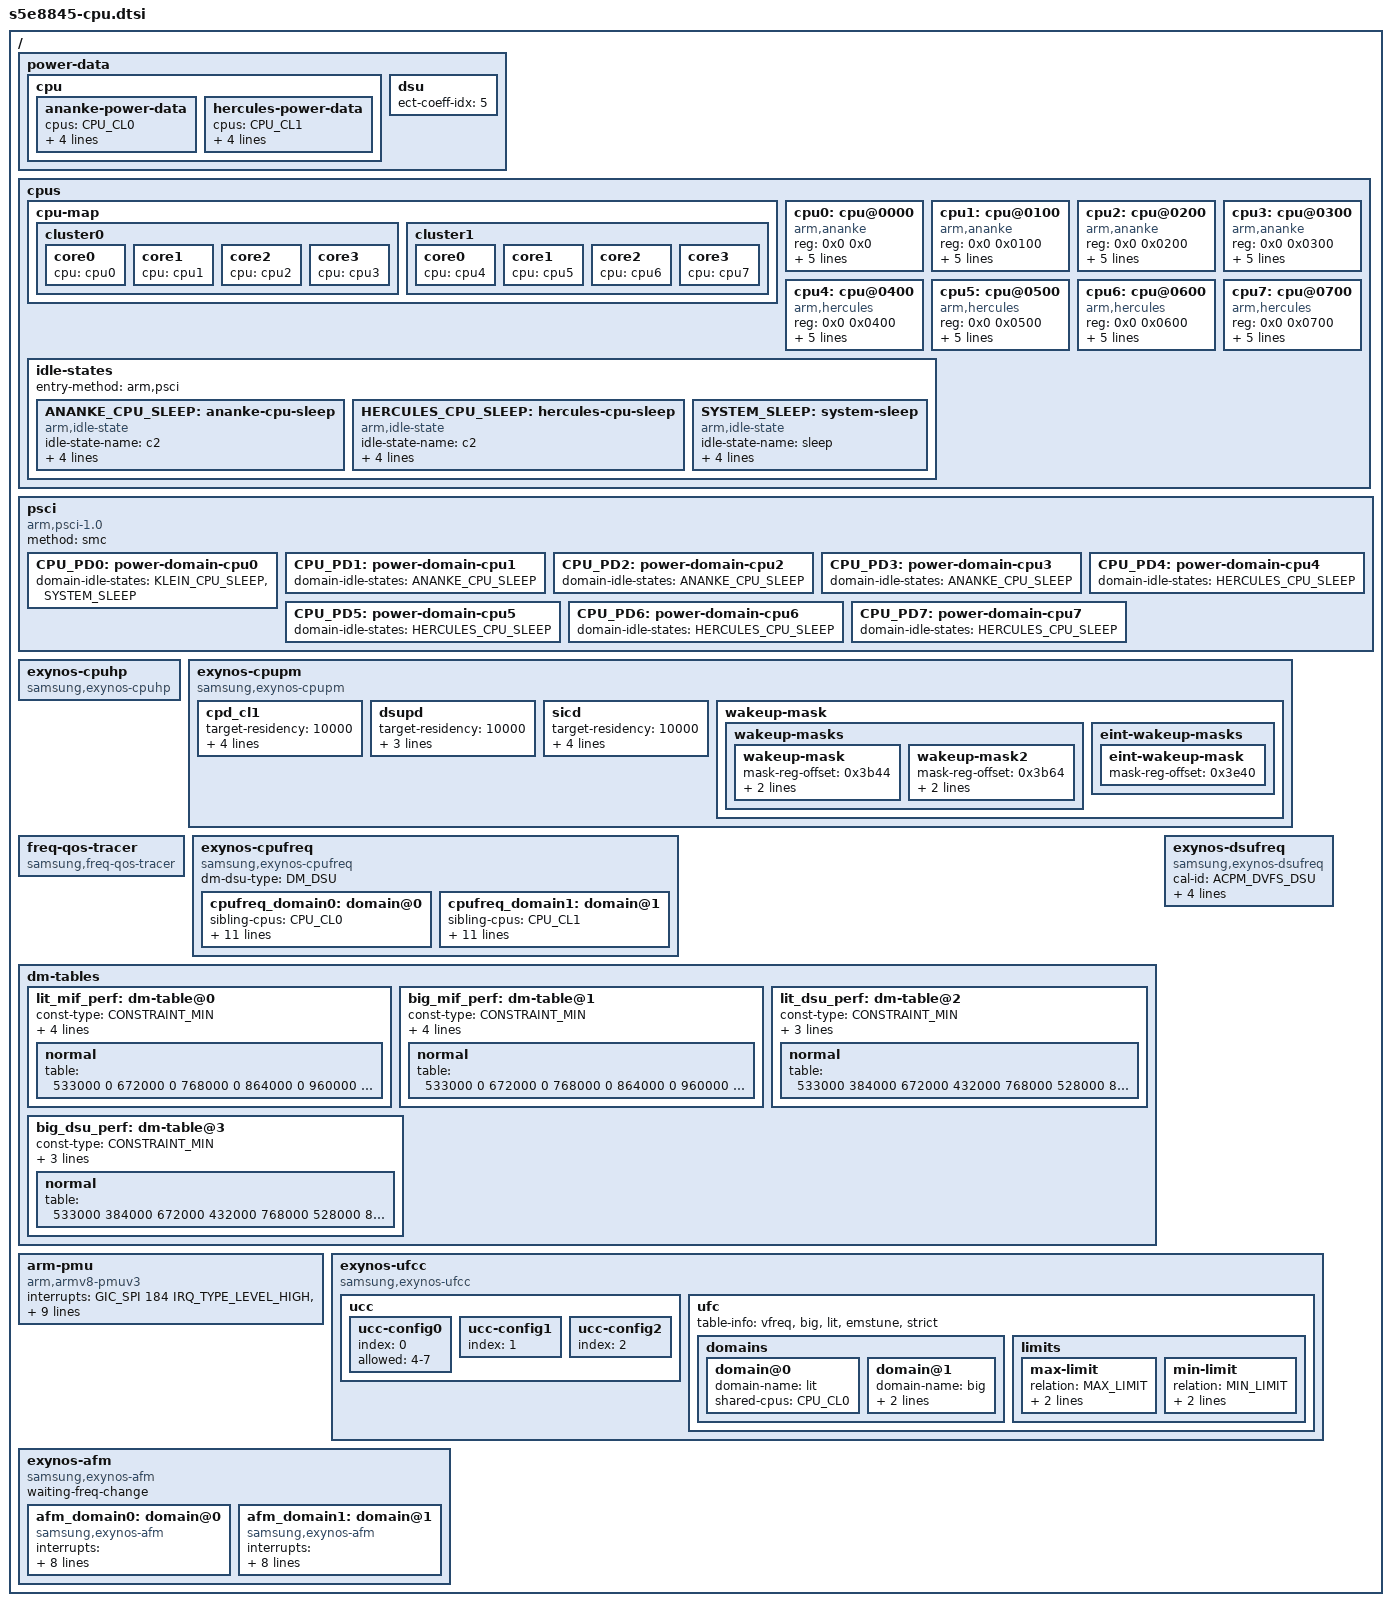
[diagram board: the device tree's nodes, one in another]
/*
 * SAMSUNG S5E8845 SoC CPU device tree source
 *
 * Copyright (c) 2023 Samsung Electronics Co., Ltd.
 *             http://www.samsung.com
 *
 * SAMSUNG EXYNOS8845 SoC device nodes are listed in this file.
 * EXYNOS based board files can include this file and provide
 * values for board specfic bindings.
 *
 * This program is free software; you can redistribute it and/or modify
 * it under the terms of the GNU General Public License version 2 as
 * published by the Free Software Foundation.
 */

#include <dt-bindings/soc/samsung/cpupm.h>

/ {

	power-data {

		#define CPU_CL0 "0-3"
		#define CPU_CL1 "4-7"
		#define CPU_ALL "0-7"

		#define CPUCL0_DMIPS_PER_MHZ 380
		#define CPUCL1_DMIPS_PER_MHZ 900

		#define CPUCL0_DP_COEFF 80
		#define CPUCL1_DP_COEFF 517

		cpu {
			ananke-power-data {
				/* default power data */
				cpus = CPU_CL0;
				capacity-dmips-mhz = <CPUCL0_DMIPS_PER_MHZ>;
				dynamic-power-coefficient = <CPUCL0_DP_COEFF>;
				tz-name = "LITTLE";

				/* dynamic power w/ ECT */
				ect-coeff-idx = <1>;
			};
			hercules-power-data {
				/* default power data */
				cpus = CPU_CL1;
				capacity-dmips-mhz = <CPUCL1_DMIPS_PER_MHZ>;
				dynamic-power-coefficient = <CPUCL1_DP_COEFF>;
				tz-name = "BIG";

				/* dynamic power w/ ECT */
				ect-coeff-idx = <0>;
			};
		};
		dsu {
			/* dynamic power w/ ECT */
			ect-coeff-idx = <5>;
		};
	};

	cpus {
		#address-cells = <2>;
		#size-cells = <0>;

		cpu-map {
			cluster0 {
				core0 {
					cpu = <&cpu0>;
				};
				core1 {
					cpu = <&cpu1>;
				};
				core2 {
					cpu = <&cpu2>;
				};
				core3 {
					cpu = <&cpu3>;
				};
			};
			cluster1 {
				core0 {
					cpu = <&cpu4>;
				};
				core1 {
					cpu = <&cpu5>;
				};
				core2 {
					cpu = <&cpu6>;
				};
				core3 {
					cpu = <&cpu7>;
				};
			};
		};

		cpu0: cpu@0000 {
			device_type = "cpu";
			compatible = "arm,ananke", "arm,armv8";
			reg = <0x0 0x0>;
			capacity-dmips-mhz = <CPUCL0_DMIPS_PER_MHZ>;
			dynamic-power-coefficient = <CPUCL0_DP_COEFF>;
			enable-method = "psci";
			cpu-idle-states = <&ANANKE_CPU_SLEEP>;
			power-domains = <&CPU_PD0>;
			power-domain-names = "psci";
		};
		cpu1: cpu@0100 {
			device_type = "cpu";
			compatible = "arm,ananke", "arm,armv8";
			reg = <0x0 0x0100>;
			capacity-dmips-mhz = <CPUCL0_DMIPS_PER_MHZ>;
			dynamic-power-coefficient = <CPUCL0_DP_COEFF>;
			enable-method = "psci";
			cpu-idle-states = <&ANANKE_CPU_SLEEP>;
			power-domains = <&CPU_PD1>;
			power-domain-names = "psci";
		};
		cpu2: cpu@0200 {
			device_type = "cpu";
			compatible = "arm,ananke", "arm,armv8";
			reg = <0x0 0x0200>;
			capacity-dmips-mhz = <CPUCL0_DMIPS_PER_MHZ>;
			dynamic-power-coefficient = <CPUCL0_DP_COEFF>;
			enable-method = "psci";
			cpu-idle-states = <&ANANKE_CPU_SLEEP>;
			power-domains = <&CPU_PD2>;
			power-domain-names = "psci";
		};
		cpu3: cpu@0300 {
			device_type = "cpu";
			compatible = "arm,ananke", "arm,armv8";
			reg = <0x0 0x0300>;
			capacity-dmips-mhz = <CPUCL0_DMIPS_PER_MHZ>;
			dynamic-power-coefficient = <CPUCL0_DP_COEFF>;
			enable-method = "psci";
			cpu-idle-states = <&ANANKE_CPU_SLEEP>;
			power-domains = <&CPU_PD3>;
			power-domain-names = "psci";
		};
		cpu4: cpu@0400 {
			device_type = "cpu";
			compatible = "arm,hercules", "arm,armv8";
			reg = <0x0 0x0400>;
			capacity-dmips-mhz = <CPUCL1_DMIPS_PER_MHZ>;
			dynamic-power-coefficient = <CPUCL1_DP_COEFF>;
			enable-method = "psci";
			cpu-idle-states = <&HERCULES_CPU_SLEEP>;
			power-domains = <&CPU_PD4>;
			power-domain-names = "psci";
		};
		cpu5: cpu@0500 {
			device_type = "cpu";
			compatible = "arm,hercules", "arm,armv8";
			reg = <0x0 0x0500>;
			capacity-dmips-mhz = <CPUCL1_DMIPS_PER_MHZ>;
			dynamic-power-coefficient = <CPUCL1_DP_COEFF>;
			enable-method = "psci";
			cpu-idle-states = <&HERCULES_CPU_SLEEP>;
			power-domains = <&CPU_PD5>;
			power-domain-names = "psci";
		};
		cpu6: cpu@0600 {
			device_type = "cpu";
			compatible = "arm,hercules", "arm,armv8";
			reg = <0x0 0x0600>;
			capacity-dmips-mhz = <CPUCL1_DMIPS_PER_MHZ>;
			dynamic-power-coefficient = <CPUCL1_DP_COEFF>;
			enable-method = "psci";
			cpu-idle-states = <&HERCULES_CPU_SLEEP>;
			power-domains = <&CPU_PD6>;
			power-domain-names = "psci";
		};
		cpu7: cpu@0700 {
			device_type = "cpu";
			compatible = "arm,hercules", "arm,armv8";
			reg = <0x0 0x0700>;
			capacity-dmips-mhz = <CPUCL1_DMIPS_PER_MHZ>;
			dynamic-power-coefficient = <CPUCL1_DP_COEFF>;
			enable-method = "psci";
			cpu-idle-states = <&HERCULES_CPU_SLEEP>;
			power-domains = <&CPU_PD7>;
			power-domain-names = "psci";
		};

		idle-states {
			entry-method = "arm,psci";

			ANANKE_CPU_SLEEP: ananke-cpu-sleep {
				idle-state-name = "c2";
				compatible = "arm,idle-state";
				arm,psci-suspend-param = <0x0010000>;
				entry-latency-us = <70>;
				exit-latency-us = <160>;
				min-residency-us = <2000>;
				status = "okay";
			};

			HERCULES_CPU_SLEEP: hercules-cpu-sleep {
				idle-state-name = "c2";
				compatible = "arm,idle-state";
				arm,psci-suspend-param = <0x0010000>;
				entry-latency-us = <150>;
				exit-latency-us = <190>;
				min-residency-us = <2500>;
				status = "okay";
			};

			SYSTEM_SLEEP: system-sleep {
				idle-state-name = "sleep";
				compatible = "arm,idle-state";
				arm,psci-suspend-param = <0x3010000>;
				entry-latency-us = <2147483647>;
				exit-latency-us = <2147483647>;
				min-residency-us = <4294967295>;
				status = "okay";
			};
		};
	};

	psci {
		compatible = "arm,psci-1.0";
		method = "smc";

		CPU_PD0: power-domain-cpu0 {
		#power-domain-cells = <0>;
		domain-idle-states = <&KLEIN_CPU_SLEEP>, <&SYSTEM_SLEEP>;
		};
		CPU_PD1: power-domain-cpu1 {
		#power-domain-cells = <0>;
		domain-idle-states = <&ANANKE_CPU_SLEEP>;
		};
		CPU_PD2: power-domain-cpu2 {
		#power-domain-cells = <0>;
		domain-idle-states = <&ANANKE_CPU_SLEEP>;
		};
		CPU_PD3: power-domain-cpu3 {
		#power-domain-cells = <0>;
		domain-idle-states = <&ANANKE_CPU_SLEEP>;
		};
		CPU_PD4: power-domain-cpu4 {
		#power-domain-cells = <0>;
		domain-idle-states = <&HERCULES_CPU_SLEEP>;
		};
		CPU_PD5: power-domain-cpu5 {
		#power-domain-cells = <0>;
		domain-idle-states = <&HERCULES_CPU_SLEEP>;
		};
		CPU_PD6: power-domain-cpu6 {
		#power-domain-cells = <0>;
		domain-idle-states = <&HERCULES_CPU_SLEEP>;
		};
		CPU_PD7: power-domain-cpu7 {
		#power-domain-cells = <0>;
		domain-idle-states = <&HERCULES_CPU_SLEEP>;
		};
	};

	exynos-cpuhp {
		compatible = "samsung,exynos-cpuhp";
		status = "okay";
	};

	exynos-cpupm {
		compatible = "samsung,exynos-cpupm";
		status = "okay";

		cpd_cl1 {
			device_type = "cpupm";
			target-residency = <10000>;
			type = <POWERMODE_TYPE_CLUSTER>;
			cal-id = <1>;
			siblings = CPU_CL1;
			entry-allowed = CPU_CL1;
		};

		dsupd {
			device_type = "cpupm";
			target-residency = <10000>;
			type = <POWERMODE_TYPE_DSU>;
			siblings = CPU_ALL;
			entry-allowed = CPU_ALL;
		};

		sicd {
			device_type = "cpupm";
			target-residency = <10000>;
			type = <POWERMODE_TYPE_SYSTEM>;
			siblings = CPU_ALL;
			entry-allowed = CPU_ALL;
			deferred-enabled;
		};

		wakeup-mask {
			wakeup-masks {
				wakeup-mask {
					mask-reg-offset = <0x3b44>;
					stat-reg-offset = <0x3b50>;
					mask = <0xff000000>;
				};
				wakeup-mask2 {
					mask-reg-offset = <0x3b64>;
					stat-reg-offset = <0x3b54>;
					mask = <0x00>;
				};
			};

			eint-wakeup-masks {
				eint-wakeup-mask {
					mask-reg-offset = <0x3e40>;
				};
			};
		};

	};

	freq-qos-tracer {
		compatible = "samsung,freq-qos-tracer";
		status = "okay";
	};

	exynos-cpufreq {
		compatible = "samsung,exynos-cpufreq";
		status = "okay";
		dm-dsu-type = <DM_DSU>;

		cpufreq_domain0: domain@0 {
			sibling-cpus = CPU_CL0;
			cal-id = <ACPM_DVFS_CPUCL0>;
			dm-type = <DM_CPUCL0>;
			dss-type = <ESS_FLAG_CPU_CL0>;

			max-freq = <2050000>;
			min-freq = <533000>;

			fast-switch;
			thread-run-on = "0-3";

			#cooling-cells = <2>; /* min followed by max */
			ect-coeff-index = <1>;
			tz-cooling-name = "LITTLE";

			freq-table = <   533000
					 672000
					 768000
					 864000
					 960000
					1056000
					1152000
					1248000
					1344000
					1440000
					1536000
					1632000
					1728000
					1824000
					1920000
					2050000 >;
		};

		cpufreq_domain1: domain@1 {
			sibling-cpus = CPU_CL1;
			cal-id = <ACPM_DVFS_CPUCL1>;
			dm-type = <DM_CPUCL1>;
			dss-type = <ESS_FLAG_CPU_CL1>;

			max-freq = <2750000>;
			min-freq = <533000>;

			fast-switch;
			thread-run-on = "0-3";

			#cooling-cells = <2>; /* min followed by max */
			ect-coeff-index = <0>;
			tz-cooling-name = "BIG";

			freq-table = <   533000
					 672000
					 768000
					 864000
					 960000
					1056000
					1152000
					1248000
					1344000
					1440000
					1536000
					1632000
					1728000
					1824000
					1920000
					2016000
					2112000
					2208000
					2304000
					2400000
					2496000
					2592000
					2688000
					2750000 >;
		};
	};

	dm-tables {
		lit_mif_perf: dm-table@0 {
			const-type = <CONSTRAINT_MIN>;
			dm-slave = <DM_MIF>;
			master-cal-id = <ACPM_DVFS_CPUCL0>;
			slave-cal-id = <ACPM_DVFS_MIF>;
			dynamic-disable;

			normal {        /* CPU    MIF */
				table = <  533000        0
					   672000        0
					   768000        0
					   864000        0
					   960000        0
					  1056000        0
					  1152000        0
					  1248000        0
					  1344000        0
					  1440000        0
					  1536000        0
					  1632000        0
					  1728000        0
					  1824000        0
					  1920000        0
					  2050000        0 >;
			};
		};
		big_mif_perf: dm-table@1 {
			const-type = <CONSTRAINT_MIN>;
			dm-slave = <DM_MIF>;
			master-cal-id = <ACPM_DVFS_CPUCL1>;
			slave-cal-id = <ACPM_DVFS_MIF>;
			dynamic-disable;

			normal {        /* CPU    MIF */
				table = <  533000        0
					   672000        0
					   768000        0
					   864000        0
					   960000        0
					  1056000        0
					  1152000        0
					  1248000        0
					  1344000        0
					  1440000        0
					  1536000        0
					  1632000        0
					  1728000        0
					  1824000        0
					  1920000        0
					  2016000  2093000
					  2112000  2288000
					  2208000  2288000
					  2304000  2535000
					  2400000  2730000
					  2496000  3172000
					  2592000  3172000
					  2688000  3172000
					  2750000  3172000 >;
			};
		};
		lit_dsu_perf: dm-table@2 {
			const-type = <CONSTRAINT_MIN>;
			dm-slave = <DM_DSU>;
			master-cal-id = <ACPM_DVFS_CPUCL0>;
			slave-cal-id = <ACPM_DVFS_DSU>;

			normal {        /* CPU    DSU */
				table = <  533000   384000
					   672000   432000
					   768000   528000
					   864000   576000
					   960000   624000
					  1056000   720000
					  1152000   768000
					  1248000   816000
					  1344000   912000
					  1440000   960000
					  1536000  1008000
					  1632000  1104000
					  1728000  1152000
					  1824000  1200000
					  1920000  1248000
					  2050000  1344000 >;
			};
		};
		big_dsu_perf: dm-table@3 {
			const-type = <CONSTRAINT_MIN>;
			dm-slave = <DM_DSU>;
			master-cal-id = <ACPM_DVFS_CPUCL1>;
			slave-cal-id = <ACPM_DVFS_DSU>;

			normal {        /* CPU    DSU */
				table = <  533000   384000
					   672000   432000
					   768000   528000
					   864000   576000
					   960000   624000
					  1056000   720000
					  1152000   768000
					  1248000   816000
					  1344000   912000
					  1440000   960000
					  1536000  1008000
					  1632000  1104000
					  1728000  1152000
					  1824000  1200000
					  1920000  1248000
					  2016000  1344000
					  2112000  1440000
					  2208000  1536000
					  2304000  1632000
					  2400000  1680000
					  2496000  1728000
					  2592000  1776000
					  2688000  1872000
					  2750000  1920000 >;
			};
		};
	};

	exynos-dsufreq {
		compatible = "samsung,exynos-dsufreq";
		status = "okay";

		cal-id = <ACPM_DVFS_DSU>;
		dm-type = <DM_DSU>;
		dss-type = <ESS_FLAG_DSU>;

		freq-table = <	288000
				384000
				480000
				576000
				672000
				768000
				864000
				960000
				1056000
				1152000
				1248000
				1344000
				1536000
				1632000
				1728000
				1824000
				1920000
				2016000	>;
	};

	arm-pmu {
		compatible = "arm,armv8-pmuv3";
		interrupts = <GIC_SPI 184 IRQ_TYPE_LEVEL_HIGH>,
			<GIC_SPI 185 IRQ_TYPE_LEVEL_HIGH>,
			<GIC_SPI 186 IRQ_TYPE_LEVEL_HIGH>,
			<GIC_SPI 187 IRQ_TYPE_LEVEL_HIGH>,
			<GIC_SPI 188 IRQ_TYPE_LEVEL_HIGH>,
			<GIC_SPI 189 IRQ_TYPE_LEVEL_HIGH>,
			<GIC_SPI 190 IRQ_TYPE_LEVEL_HIGH>,
			<GIC_SPI 191 IRQ_TYPE_LEVEL_HIGH>;
		interrupt-affinity = <&cpu0>, <&cpu1>, <&cpu2>,
			<&cpu3>, <&cpu4>, <&cpu5>,
			<&cpu6>, <&cpu7>;
	};

	exynos-ufcc {
		compatible = "samsung,exynos-ufcc";
		status = "okay";

		ucc {
			ucc-config0 {
				index = <0>;
				allowed = "4-7";
			};
			ucc-config1 {
				index = <1>;
			};
			ucc-config2 {
				index = <2>;
			};
		};

		ufc {
			table-info = "vfreq",
				"big",
				"lit",
				"emstune",
				"strict";

			domains {
				domain@0 {
					domain-name = "lit";
					shared-cpus = CPU_CL0;
				};
				domain@1 {
					domain-name = "big";
					shared-cpus = CPU_CL1;
					allow-disable-cpus;
				};
			};

			limits {
				/* lowest frequency at or above target */
				#define MIN_LIMIT	0
				/* highest frequency below or at target */
				#define MAX_LIMIT	1

				max-limit {
					relation = <MAX_LIMIT>;
					/* VFREQ    BIG    LIT   EMS STRICT */
					table = < 2750000 2750000 2050000 0 0
						2688000 2688000 2050000 0 0
						2592000 2592000 2050000 0 0
						2496000 2496000 2050000 0 0
						2400000 2400000 2050000 0 0
						2304000 2304000 2050000 0 0
						2208000 2208000 2050000 0 0
						2112000 2112000 2050000 0 0
						2016000 2016000 2050000 0 0
						1920000 1920000 2050000 0 0
						1824000 1824000 2050000 0 0
						1728000 1728000 2050000 0 0
						1632000 1632000 1920000 0 0
						1536000 1536000 1920000 0 0
						1440000 1440000 1824000 0 0
						1344000 1344000 1824000 0 0
						1248000 1248000 1728000 0 0
						1152000 1152000 1728000 0 0
						1056000 1056000 1632000 0 0
						 960000  960000 1632000 0 0
						 864000  864000 1536000 0 0
						 768000  768000 1536000 0 0
						 672000  672000 1536000 0 0
						 533000  533000 1536000 0 0 >;
					/* fill little freq automatically */
				};
				min-limit {
					relation = <MIN_LIMIT>;
					/* VFREQ   BIG     LIT   EMS STRICT */
					table = < 2750000 2750000 2050000 2 1
						2688000 2688000 2050000 2 1
						2592000 2592000 2050000 2 1
						2496000 2496000 2050000 2 1
						2400000 2400000 2050000 2 1
						2304000 2304000 2050000 2 1
						2208000 2208000 1536000 1 1
						2112000 2112000 1536000 1 1
						2016000 2016000 1536000 1 1
						1920000 1920000 1536000 1 1
						1824000 1824000 1536000 1 1
						1728000 1728000  960000 1 1
						1632000 1632000  960000 1 1
						1536000 1536000  960000 1 1
						1440000 1440000  960000 1 1
						1344000 1344000  960000 1 1
						1248000 1248000  768000 1 1
						1152000 1152000  768000 1 1
						1056000 1056000  768000 0 1
						 960000  960000  768000 0 1
						 864000  864000  768000 0 1
						 768000  768000  768000 0 1
						 672000  672000  768000 0 1
						 533000  533000  768000 0 1 >;
					/* fill little freq automatically */
				};
			};
		};
	};

	exynos-afm {
		#define MAIN_PMIC 1
		#define SUB_PMIC  2
		compatible = "samsung,exynos-afm";
		status = "okay";
		waiting-freq-change;

		afm_domain0: domain@0 {
			device_type = "afm-domain";
			compatible = "samsung,exynos-afm";
			interrupts = <GIC_SPI INTREQ__OCP_REATOR_CPUCL0_0 IRQ_TYPE_LEVEL_HIGH>;
			sibling-cpus = "0-3";
			interrupt-src = <SUB_PMIC>;
			s2mps-afm-offset = <0x55>;
			htu-base-addr = <0x10840000>;
			down-step = <1>;
			max-freq-wo-afm = <2002000>;
			release-duration = <15>;
		};

		afm_domain1: domain@1 {
			device_type = "afm-domain";
			compatible = "samsung,exynos-afm";
			interrupts = <GIC_SPI INTREQ__OCP_REATOR_CPUCL0_1 IRQ_TYPE_LEVEL_HIGH>;
			sibling-cpus = "4-7";
			interrupt-src = <SUB_PMIC>;
			s2mps-afm-offset = <0x31>;
			htu-base-addr = <0x10850000>;
			down-step = <1>;
			max-freq-wo-afm = <2002000>;
			release-duration = <15>;
		};
	};
};
